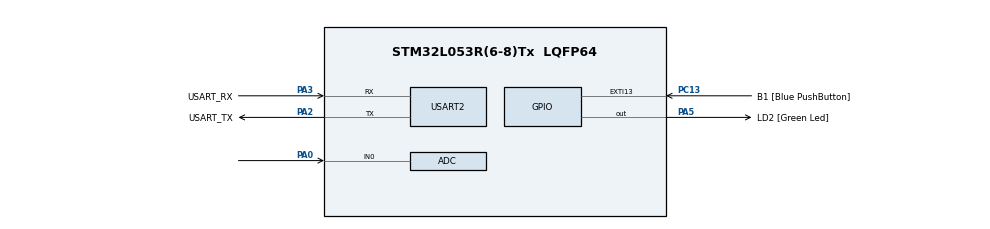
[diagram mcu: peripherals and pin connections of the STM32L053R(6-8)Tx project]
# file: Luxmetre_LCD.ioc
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Mcu.Family=STM32L0
Mcu.Name=STM32L053R(6-8)Tx
Mcu.Package=LQFP64
PA0.Mode=IN0
PA0.Signal=ADC_IN0
PA13.GPIO_Label=TMS
PA13.Mode=Serial_Wire
PA13.Signal=SYS_SWDIO
PA14.GPIO_Label=TCK
PA14.Mode=Serial_Wire
PA14.Signal=SYS_SWCLK
PA2.GPIO_Label=USART_TX
PA2.Mode=Asynchronous
PA2.Signal=USART2_TX
PA3.GPIO_Label=USART_RX
PA3.Mode=Asynchronous
PA3.Signal=USART2_RX
PA5.GPIO_Label=LD2 [Green Led]
PA5.Signal=GPIO_Output
PC13.GPIO_Label=B1 [Blue PushButton]
PC13.GPIO_ModeDefaultEXTI=GPIO_MODE_IT_FALLING
PC13.Signal=GPXTI13
PC14-OSC32_IN.Mode=LSE-External-Oscillator
PC14-OSC32_IN.Signal=RCC_OSC32_IN
PC15-OSC32_OUT.Mode=LSE-External-Oscillator
PC15-OSC32_OUT.Signal=RCC_OSC32_OUT
PH0-OSC_IN.Mode=HSE-External-Clock-Source
PH0-OSC_IN.Signal=RCC_OSC_IN
PH1-OSC_OUT.Signal=RCC_OSC_OUT
ProjectManager.HeapSize=0x200
ProjectManager.StackSize=0x400
ProjectManager.TargetToolchain=STM32CubeIDE
RCC.AHBFreq_Value=16000000
RCC.APB1Freq_Value=16000000
RCC.APB1TimFreq_Value=16000000
RCC.APB2Freq_Value=16000000
RCC.APB2TimFreq_Value=16000000
RCC.HCLKFreq_Value=16000000
RCC.HSE_VALUE=8000000
RCC.HSI16_VALUE=16000000
RCC.HSI48_VALUE=48000000
RCC.HSI_VALUE=16000000
RCC.MSI_VALUE=2097000
RCC.SYSCLKFreq_VALUE=16000000
RCC.SYSCLKSource=RCC_SYSCLKSOURCE_HSI
RCC.VCOOutputFreq_Value=48000000
USART2.VirtualMode-Asynchronous=VM_ASYNC
board=NUCLEO-L053R8

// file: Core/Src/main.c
/* USER CODE BEGIN Header */
/**
  ******************************************************************************
  * @file           : main.c
  * @brief          : Main program body
  ******************************************************************************
  * @attention
  *
  * Copyright (c) 2022 STMicroelectronics.
  * All rights reserved.
  *
  * This software is licensed under terms that can be found in the LICENSE file
  * in the root directory of this software component.
  * If no LICENSE file comes with this software, it is provided AS-IS.
  *
  ******************************************************************************
  */
/* USER CODE END Header */
#include "main.h"
#include "adc.h"
#include "usart.h"
#include "gpio.h"

void SystemClock_Config(void);

int main(void)
{

  /* MCU Configuration--------------------------------------------------------*/

  /* Reset of all peripherals, Initializes the Flash interface and the Systick. */
  LL_APB2_GRP1_EnableClock(LL_APB2_GRP1_PERIPH_SYSCFG);
  LL_APB1_GRP1_EnableClock(LL_APB1_GRP1_PERIPH_PWR);

  /* Configure the system clock */
  SystemClock_Config();

  /* USER CODE BEGIN SysInit */

  //activation de l'horloge pour GPIOA et GPIOB
  RCC->IOPENR |= RCC_IOPENR_GPIOAEN | RCC_IOPENR_GPIOBEN;
  /*Ici la fonction LL_mDelay sera utilisée pour faire des temps d'attente en us Pour cette raison on initialise le nombre de ticks nécessaire pour faire 1ms à 16000 au lieu de 16000000
  */
  LL_Init1msTick(16000);

  /* USER CODE END SysInit */

  /* Initialize all configured peripherals */
  MX_GPIO_Init();
  MX_USART2_UART_Init();
  MX_ADC_Init();

  /* USER CODE BEGIN 2 */

  //Initialisation du LCD
  lcdinit4(); //call lcdinit4
  LL_ADC_StartCalibration(ADC1);
  while(LL_ADC_IsCalibrationOnGoing(ADC1) != 0);

  /* USER CODE END 2 */
  float voltage=0;
  int Lumens=0,Resistance=0;
  uint16_t adc_value=0;
  int resistor_value=220;

  int tmpV=0,m=0,c=0,d=0,u=0;
  int tmpL=0,M100=0,M10=0,M=0,C=0,D=0,U=0;

  char Text_LCD1[16] = "Voltage u.dcm V ";
  //char Text_LCD2[16] = "Lumens MMMCDU lm";
  char Text_LCD2[16] = "Res MMMCDU ohm  ";
  /* Infinite loop */
  while (1)
  {

	    LL_ADC_Enable(ADC1);
		LL_ADC_REG_StartConversion(ADC1);
		while(LL_ADC_REG_IsConversionOngoing(ADC1) != 0);

		adc_value=LL_ADC_REG_ReadConversionData12(ADC1);

		voltage=adc_value*5.0/4095.0;

		Resistance=resistor_value * ((5.0/voltage) - 1.0); //10k * ( (Vin/Vout) -1)

		Lumens=Resistance;

		tmpV=voltage*1000;
		u=tmpV/1000; //Unite
		tmpV=tmpV%1000;
		d=tmpV/100; //Dixieme
		tmpV=tmpV%100;
		c=tmpV/10; //Centieme
		m=tmpV%10; //Milieme

		Text_LCD1[8] = u+48;
		Text_LCD1[10] = d+48;
		Text_LCD1[11] = c+48;
		Text_LCD1[12] = m+48;

		tmpL=Lumens;
		M10=tmpL/100000; //10^5
		tmpL=tmpL%100000;
		M10=tmpL/10000; //10^4
		tmpL=tmpL%10000;
		M=tmpL/1000; //10^3
		tmpL=tmpL%1000;
		C=tmpL/100; //10^2
		tmpL=tmpL%100;
		D=tmpL/10; //10^1
		U=tmpL%10; //10^0

//		Text_LCD2[7] = M100+48;
//		Text_LCD2[8] = M10+48;
//		Text_LCD2[9] = M+48;
//		Text_LCD2[10] = C+48;
//		Text_LCD2[11] = D+48;
//		Text_LCD2[12] = U+48;

		Text_LCD2[4] = M100+48;
		Text_LCD2[5] = M10+48;
		Text_LCD2[6] = M+48;
		Text_LCD2[7] = C+48;
		Text_LCD2[8] = D+48;
		Text_LCD2[9] = U+48;

		//Affichage sur le LCD
		Affichage_LCD(Text_LCD1, Text_LCD2); //call Affichage_LCD

		LL_mDelay(330000);

  }
}

void SystemClock_Config(void)
{
  LL_FLASH_SetLatency(LL_FLASH_LATENCY_0);
  while(LL_FLASH_GetLatency()!= LL_FLASH_LATENCY_0)
  {
  }
  LL_PWR_SetRegulVoltageScaling(LL_PWR_REGU_VOLTAGE_SCALE1);
  LL_RCC_HSI_Enable();

   /* Wait till HSI is ready */
  while(LL_RCC_HSI_IsReady() != 1)
  {

  }
  LL_RCC_HSI_SetCalibTrimming(16);
  LL_RCC_SetAHBPrescaler(LL_RCC_SYSCLK_DIV_1);
  LL_RCC_SetAPB1Prescaler(LL_RCC_APB1_DIV_1);
  LL_RCC_SetAPB2Prescaler(LL_RCC_APB2_DIV_1);
  LL_RCC_SetSysClkSource(LL_RCC_SYS_CLKSOURCE_HSI);

   /* Wait till System clock is ready */
  while(LL_RCC_GetSysClkSource() != LL_RCC_SYS_CLKSOURCE_STATUS_HSI)
  {

  }

  LL_Init1msTick(16000000);

  LL_SetSystemCoreClock(16000000);
  LL_RCC_SetUSARTClockSource(LL_RCC_USART2_CLKSOURCE_PCLK1);
}

void Error_Handler(void)
{
  __disable_irq();
  while (1)
  {
  }
}
